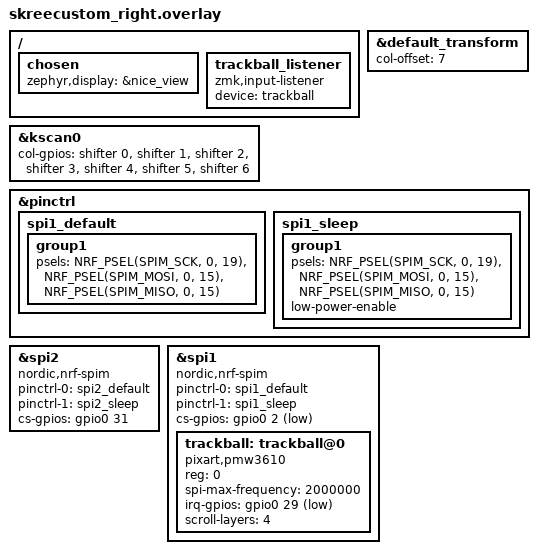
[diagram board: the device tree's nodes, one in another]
#include "skreecustom.dtsi"

 &default_transform {
    col-offset = <7>;
};

&kscan0 {
    col-gpios
        = <&shifter 0 GPIO_ACTIVE_HIGH>
        , <&shifter 1 GPIO_ACTIVE_HIGH>
        , <&shifter 2 GPIO_ACTIVE_HIGH>
        , <&shifter 3 GPIO_ACTIVE_HIGH>
        , <&shifter 4 GPIO_ACTIVE_HIGH>
        , <&shifter 5 GPIO_ACTIVE_HIGH>
        , <&shifter 6 GPIO_ACTIVE_HIGH>
//        , <&shifter 7 GPIO_ACTIVE_HIGH>
        ;
};

&pinctrl {
    spi1_default: spi1_default {
        group1 {
            psels = <NRF_PSEL(SPIM_SCK, 0, 19)>,
                <NRF_PSEL(SPIM_MOSI, 0, 15)>,
                <NRF_PSEL(SPIM_MISO, 0, 15)>;
        };
    };
    spi1_sleep: spi1_sleep {
        group1 {
            psels = <NRF_PSEL(SPIM_SCK, 0, 19)>,
                <NRF_PSEL(SPIM_MOSI, 0, 15)>,
                <NRF_PSEL(SPIM_MISO, 0, 15)>;
            low-power-enable;
        };
    };
};

nice_view_spi: &spi2 {
    compatible = "nordic,nrf-spim";
    pinctrl-0 = <&spi2_default>;
    pinctrl-1 = <&spi2_sleep>;
    pinctrl-names = "default", "sleep";
    cs-gpios = <&gpio0 31 GPIO_ACTIVE_HIGH>;
};

/ {
    chosen {
        zephyr,display = &nice_view;
    };
};

&spi1 {
    status = "okay";
    compatible = "nordic,nrf-spim";
    pinctrl-0 = <&spi1_default>;
    pinctrl-1 = <&spi1_sleep>;
    pinctrl-names = "default", "sleep";
    cs-gpios = <&gpio0 2 GPIO_ACTIVE_LOW>; 
    trackball: trackball@0 {
        status = "okay";
        compatible = "pixart,pmw3610";
        reg = <0>;
        spi-max-frequency = <2000000>;
        irq-gpios = <&gpio0 29 (GPIO_ACTIVE_LOW | GPIO_PULL_UP)>; 
        scroll-layers = <4>;
    };
};
/ {
  trackball_listener {
    compatible = "zmk,input-listener";
    device = <&trackball>;
  };
};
